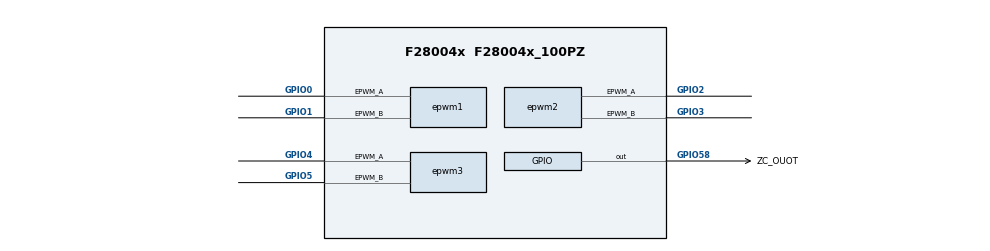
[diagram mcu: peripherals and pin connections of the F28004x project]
/**
 * @cliArgs --device "F28004x" --part "F28004x_100PZ" --package "F28004x_100PZ" --context "system" --product "C2000WARE@5.04.00.00"
 * @versions {"tool":"1.24.0+4110"}
 */

/**
 * Import the modules used in this configuration.
 */
const adc       = scripting.addModule("/driverlib/adc.js", {}, false);
const adc1      = adc.addInstance();
const asysctl   = scripting.addModule("/driverlib/asysctl.js");
const cla       = scripting.addModule("/driverlib/cla.js", {}, false);
const cla1      = cla.addInstance();
const cputimer  = scripting.addModule("/driverlib/cputimer.js", {}, false);
const cputimer1 = cputimer.addInstance();
const epwm      = scripting.addModule("/driverlib/epwm.js", {}, false);
const epwm1     = epwm.addInstance();
const epwm2     = epwm.addInstance();
const epwm3     = epwm.addInstance();
const gpio      = scripting.addModule("/driverlib/gpio.js", {}, false);
const gpio1     = gpio.addInstance();
const memcfg    = scripting.addModule("/driverlib/memcfg.js");

/**
 * Write custom configuration values to the imported modules.
 */
adc1.adcClockPrescaler              = "ADC_CLK_DIV_2_0";
adc1.enabledSOCs                    = ["ADC_SOC_NUMBER0"];
adc1.soc0Channel                    = "ADC_CH_ADCIN5";
adc1.soc0Trigger                    = "ADC_TRIGGER_EPWM1_SOCA";
adc1.soc0SampleWindow               = 8;
adc1.enabledInts                    = ["ADC_INT_NUMBER1"];
adc1.$name                          = "myADCA";
adc1.interruptPulseMode             = "ADC_PULSE_END_OF_CONV";
adc1.enableInterrupt1ContinuousMode = true;
adc1.enableInterrupt1               = true;

cla1.$name              = "myCLA0";
cla1.enable_CLA_TASK_2  = false;
cla1.enable_CLA_TASK_3  = false;
cla1.enable_CLA_TASK_4  = false;
cla1.enable_CLA_TASK_6  = false;
cla1.enable_CLA_TASK_7  = false;
cla1.enable_CLA_TASK_5  = false;
cla1.trigger_CLA_TASK_1 = "CLA_TRIGGER_ADCA1";
cla1.cpuint_CLA_TASK_2  = false;
cla1.cpuint_CLA_TASK_3  = false;
cla1.cpuint_CLA_TASK_5  = false;
cla1.cpuint_CLA_TASK_6  = false;
cla1.cpuint_CLA_TASK_4  = false;
cla1.cpuint_CLA_TASK_7  = false;
cla1.cpuint_CLA_TASK_8  = false;

cputimer1.$name                    = "myCPUTIMER0";
cputimer1.timerPeriod              = 4999;
cputimer1.startTimer               = true;
cputimer1.enableInterrupt          = true;
cputimer1.registerInterrupts       = true;
cputimer1.timerInt.enableInterrupt = true;

epwm1.$name                                             = "myEPWM1";
epwm1.epwmTimebase_hsClockDiv                           = "EPWM_HSCLOCK_DIVIDER_4";
epwm1.epwmTimebase_counterMode                          = "EPWM_COUNTER_MODE_UP";
epwm1.epwmEventTrigger_EPWM_SOC_A_triggerEnable         = true;
epwm1.epwmTimebase_emulationMode                        = "EPWM_EMULATION_FREE_RUN";
epwm1.epwmEventTrigger_EPWM_SOC_A_triggerSource         = "EPWM_SOC_TBCTR_PERIOD";
epwm1.epwmEventTrigger_EPWM_SOC_A_triggerEventPrescalar = "1";
epwm1.epwmTimebase_syncOutPulseMode                     = "EPWM_SYNC_OUT_PULSE_ON_COUNTER_ZERO";
epwm1.epwmTimebase_period                               = 1249;
epwm1.epwm.$assign                                      = "EPWM1";
epwm1.epwm.epwm_aPin.$assign                            = "GPIO0";
epwm1.epwm.epwm_bPin.$assign                            = "GPIO1";

epwm2.$name                                                    = "myEPWM2";
epwm2.epwmTimebase_hsClockDiv                                  = "EPWM_HSCLOCK_DIVIDER_4";
epwm2.epwmTimebase_counterMode                                 = "EPWM_COUNTER_MODE_UP";
epwm2.epwmEventTrigger_EPWM_SOC_A_triggerEnable                = true;
epwm2.epwmTimebase_emulationMode                               = "EPWM_EMULATION_FREE_RUN";
epwm2.epwmEventTrigger_EPWM_SOC_A_triggerSource                = "EPWM_SOC_TBCTR_PERIOD";
epwm2.epwmEventTrigger_EPWM_SOC_A_triggerEventPrescalar        = "1";
epwm2.epwmTimebase_phaseEnable                                 = true;
epwm2.epwmCounterCompare_cmpA                                  = 999;
epwm2.epwmActionQualifier_EPWM_AQ_OUTPUT_A_ON_TIMEBASE_ZERO    = "EPWM_AQ_OUTPUT_HIGH";
epwm2.epwmActionQualifier_EPWM_AQ_OUTPUT_A_ON_TIMEBASE_UP_CMPA = "EPWM_AQ_OUTPUT_LOW";
epwm2.epwmTimebase_period                                      = 1249;
epwm2.epwm.$assign                                             = "EPWM2";
epwm2.epwm.epwm_aPin.$assign                                   = "GPIO2";
epwm2.epwm.epwm_bPin.$assign                                   = "GPIO3";

epwm3.$name                                                    = "myEPWM3";
epwm3.epwmTimebase_hsClockDiv                                  = "EPWM_HSCLOCK_DIVIDER_4";
epwm3.epwmTimebase_counterMode                                 = "EPWM_COUNTER_MODE_UP";
epwm3.epwmEventTrigger_EPWM_SOC_A_triggerEnable                = true;
epwm3.epwmTimebase_emulationMode                               = "EPWM_EMULATION_FREE_RUN";
epwm3.epwmEventTrigger_EPWM_SOC_A_triggerSource                = "EPWM_SOC_TBCTR_PERIOD";
epwm3.epwmEventTrigger_EPWM_SOC_A_triggerEventPrescalar        = "1";
epwm3.epwmTimebase_phaseEnable                                 = true;
epwm3.epwmCounterCompare_cmpA                                  = 999;
epwm3.epwmActionQualifier_EPWM_AQ_OUTPUT_A_ON_TIMEBASE_ZERO    = "EPWM_AQ_OUTPUT_HIGH";
epwm3.epwmActionQualifier_EPWM_AQ_OUTPUT_A_ON_TIMEBASE_UP_CMPA = "EPWM_AQ_OUTPUT_LOW";
epwm3.epwmTimebase_period                                      = 1249;
epwm3.epwm.$assign                                             = "EPWM3";
epwm3.epwm.epwm_aPin.$assign                                   = "GPIO4";
epwm3.epwm.epwm_bPin.$assign                                   = "GPIO5";

gpio1.$name           = "ZC_OUOT";
gpio1.direction       = "GPIO_DIR_MODE_OUT";
gpio1.gpioPin.$assign = "GPIO58";

memcfg.config_MEMCFG_SECT_LS0 = "CLA_prog";
memcfg.config_MEMCFG_SECT_LS1 = "CLA_data";
